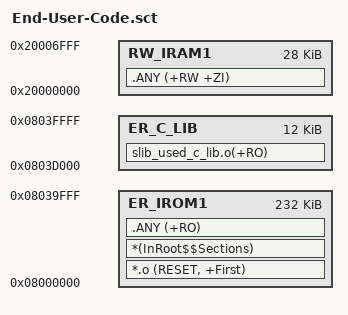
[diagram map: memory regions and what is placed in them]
; *************************************************************
; *** Scatter-Loading Description File generated by uVision ***
; *************************************************************

LR_IROM1 0x08000000 0x0003A000  {    ; load region size_region
  ER_IROM1 0x08000000 0x0003A000  {  ; load address = execution address
   *.o (RESET, +First)
   *(InRoot$$Sections)
   .ANY (+RO)
  }
  RW_IRAM1 0x20000000 0x00007000  {  ; RW data
   .ANY (+RW +ZI)
  }
  
 ; 0x20007000 0x00001000  RAM reserved for SLIB code
      
}

; 0x0803A000 ~ 0x0803CFFF reserved for SLIB protected area

LR_C_LIB 0x0803D000 0x00003000  {
  ER_C_LIB 0x0803D000 0x00003000  {  ; load address = execution address
	slib_used_c_lib.o(+RO)
  }
}

